# GPMC0_CFG register map
Vendor: Texas Instruments
Peripheral module from a debugger description file (folder am65x).
Registers are 32-bit, access per field, reset 0x0 unless marked. A register's access mark holds for its fields unless they carry their own. Offsets are as the file gives them; lines under a group give offsets from that group; [hi:lo] are bit positions; {n}, {i} and the like mark numbered series; 'fields as' and 'values as' point back to an identical list; <NAME> marks a mode.

## GPMC0_CFG
0x00 GPMC_REVISION ro reset 0x60 — This register contains the IP revision code.
  [31:0] REVISION — TI internal data. Identifies revision of peripheral.
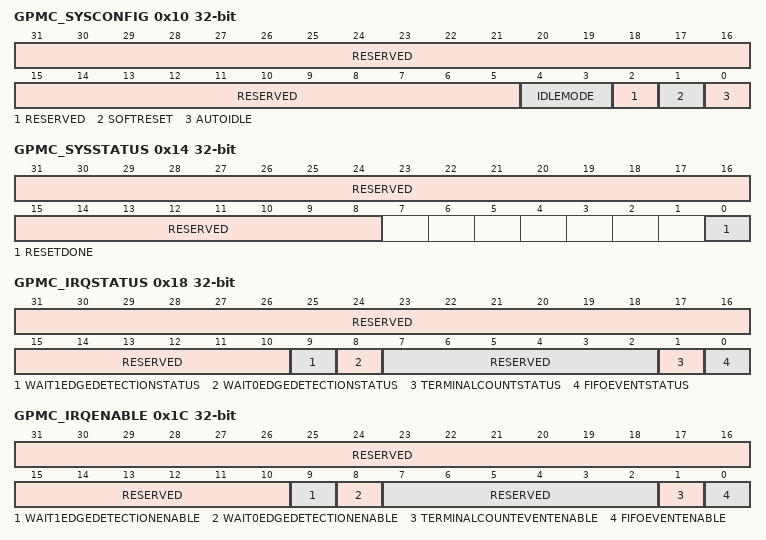
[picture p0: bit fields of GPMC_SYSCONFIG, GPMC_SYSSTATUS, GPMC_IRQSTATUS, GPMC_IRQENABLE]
0x10 GPMC_SYSCONFIG — Register related to module software reset and local power management.
  [31:5] RESERVED ro — Write 0s for future compatibility. Read returns 0.
  [4:3] IDLEMODE rw — 0h = Force-idle. A clock stop request is acknowledged unconditionally. 1h (R/W) = No-idle. A clock stop request is never acknowledged. 2h (R/W) = Smart-idle. Acknowledgment to a clock stop request is given based on the internal activity of the module. 3h (R/W) = Reserved. Do not use.
  [2] RESERVED ro — Write 0 for future compatibility Read returns 0.
  [1] SOFTRESET rw — Software reset. 0h (R/W) = Normal mode 1h (R/W) = The module is reset.
  [0] AUTOIDLE rw — Internal interface clock-gating strategy 0h (R/W) = Interface clock is free-running. 1h (R/W) = Automatic Interface clock gating strategy is applied, based on the interconnect activity.
0x14 GPMC_SYSSTATUS ro (reset mask 0xFFFFFFFE) — This register provides status information about the module, excluding the interrupt status information.
  [31:8] RESERVED — Read returns 0.
  [0] RESETDONE — Internal reset monitoring 0h (R) = Internal module reset is ongoing. 1h (R) = Reset is complete.
0x18 GPMC_IRQSTATUS — This interrupt status register regroups all the status of the module internal events that can generate an interrupt.
  [31:10] RESERVED ro — Write 0s for future compatibility. Read returns 0s.
  [9] WAIT1EDGEDETECTIONSTATUS rw — Status of the Wait1 Edge Detection interrupt Write: 0h = WAIT1EDGEDETECTIONSTATUS bit is unchanged. 1h = WAIT1EDGEDETECTIONSTATUS bit is reset. Read: 0h = A transition on WAIT1 input pin has not been detected. 1h = A transition on WAIT1 input pin has been detected.
  [8] WAIT0EDGEDETECTIONSTATUS rw — Status of the Wait0 Edge Detection interrupt Write: 0h = WAIT0EDGEDETECTIONSTATUS bit is unchanged. 1h = WAIT0EDGEDETECTIONSTATUS bit is reset. Read: 0h = A transition on WAIT0 input pin has not been detected. 1h = A transition on WAIT0 input pin has been detected.
  [7:2] RESERVED ro — Write 0s for future compatibility. Read returns 0s.
  [1] TERMINALCOUNTSTATUS rw — Status of the TerminalCountEvent interrupt Write: 0h = TERMINALCOUNTSTATUS bit is unchanged. 1h = TERMINALCOUNTSTATUS bit is reset. Read: 0h = Indicates that CountValue is greater than 0. 1h = Indicates that CountValue is equal to 0.
  [0] FIFOEVENTSTATUS rw — Status of the FIFOEvent interrupt Write: 0h = FIFOEVENTSTATUS bit is unchanged. 1h = FIFOEVENTSTATUS bit is reset. Read: 0h = Indicates that less than 1h = Indicates that at least
0x1C GPMC_IRQENABLE — The interrupt enable register allows to mask/unmask the module internal sources of interrupt, on a event-by-event basis.
  [31:10] RESERVED ro — Write 0s for future compatibility. Read returns 0s.
  [9] WAIT1EDGEDETECTIONENABLE rw — Enables the Wait1 Edge Detection interrupt 0h (R/W) = Wait1EdgeDetection interrupt is masked. 1h (R/W) = Wait1EdgeDetection event generates an interrupt if occurs.
  [8] WAIT0EDGEDETECTIONENABLE rw — Enables the Wait0 Edge Detection interrupt 0h (R/W) = Wait0EdgeDetection interrupt is masked. 1h (R/W) = Wait0EdgeDetection event generates an interrupt if occurs.
  [7:2] RESERVED ro — Write 0s for future compatibility. Read returns 0s.
  [1] TERMINALCOUNTEVENTENABLE rw — Enables TerminalCountEvent interrupt issuing in prefetch or write-posting mode 0h (R/W) = TerminalCountEvent interrupt is masked. 1h (R/W) = TerminalCountEvent interrupt is not masked.
  [0] FIFOEVENTENABLE rw — Enables the FIFOEvent interrupt 0h (R/W) = FIFOEvent interrupt is masked. 1h (R/W) = FIFOEvent interrupt is not masked.
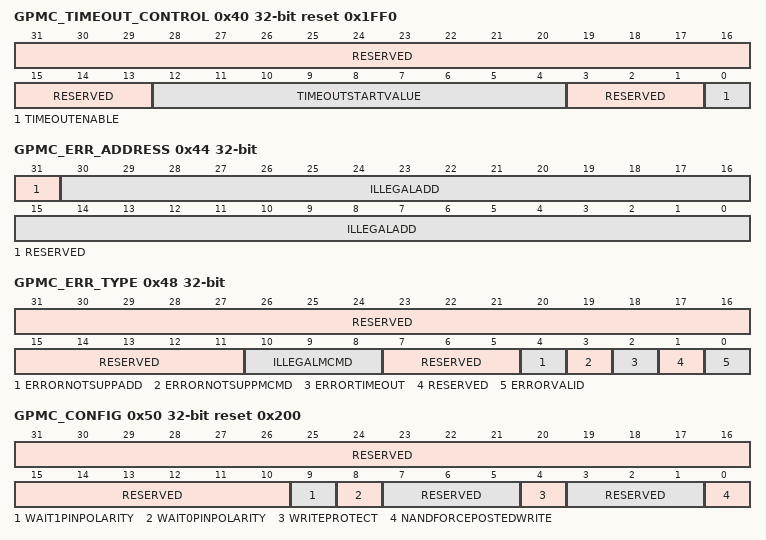
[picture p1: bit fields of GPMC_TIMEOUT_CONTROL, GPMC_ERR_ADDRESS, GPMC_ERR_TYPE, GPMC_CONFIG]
0x40 GPMC_TIMEOUT_CONTROL reset 0x1FF0 — The register allows the user to set the start value of the timeout counter.
  [31:13] RESERVED ro — Write 0s for future compatibility. Read returns 0s.
  [12:4] TIMEOUTSTARTVALUE rw — Start value of the time-out counter
  [3:1] RESERVED ro — Write 0s for future compatibility. Read returns 0s.
  [0] TIMEOUTENABLE rw — Enable bit of the TimeOut feature 0h (R/W) = TimeOut feature is disabled. 1h (R/W) = TimeOut feature is enabled.
0x44 GPMC_ERR_ADDRESS ro — The register stores the address of the illegal access when an error occurs.
  [31] RESERVED — Write 0s for future compatibility. Read returns 0.
  [30:0] ILLEGALADD — Address of illegal access
0x48 GPMC_ERR_TYPE access not given — The register stores the type of error when an error occurs.
  [31:11] RESERVED ro — Write 0s for future compatibility. Read returns 0s.
  [10:8] ILLEGALMCMD ro — System command of the transaction that caused the error
  [7:5] RESERVED ro — Write 0s for future compatibility. Read returns 0s.
  [4] ERRORNOTSUPPADD ro — Not supported address error 0h (R) = No error occurs. 1h (R) = The error is due to a nonsupported address.
  [3] ERRORNOTSUPPMCMD ro — Not supported command error 0h (R) = No error occurs. 1h (R) = The error is due to a nonsupported command
  [2] ERRORTIMEOUT ro — Time-out error 0h (R) = No error occurs. 1h (R) = The error is due to a timeout.
  [1] RESERVED ro — Write 0s for future compatibility. Read returns 0.
  [0] ERRORVALID — Error validity status - Must be explicitly cleared with a write 1 transaction 0h (R/W) = All error fields no longer valid 1h (R/W) = Error detected and logged in the other error fields (access RW1C)
0x50 GPMC_CONFIG reset 0x200 — The configuration register allows global configuration of the GPMC.
  [31:10] RESERVED ro — Write 0s for future compatibility. Read returns 0s.
  [9] WAIT1PINPOLARITY rw — Selects the polarity of input pin WAIT1 0h (R/W) = WAIT1 active low 1h (R/W) = WAIT1 active high
  [8] WAIT0PINPOLARITY rw — Selects the polarity of input pin WAIT0 0h (R/W) = WAIT0 active low 1h (R/W) = WAIT0 active high
  [7:5] RESERVED ro — Write 0s for future compatibility. Read returns 0s.
  [4] WRITEPROTECT rw — Controls the WP output pin level 0h (R/W) = nWP output pin is low 1h (R/W) = nWP output pin is high
  [3:1] RESERVED ro — Write 0s for future compatibility. Read returns 0s.
  [0] NANDFORCEPOSTEDWRITE rw — Enables the Force Posted Write feature to NAND Cmd/Add/Data location 0h (R/W) = Disables Force Posted Write 1h (R/W) = Enables Force Posted Write
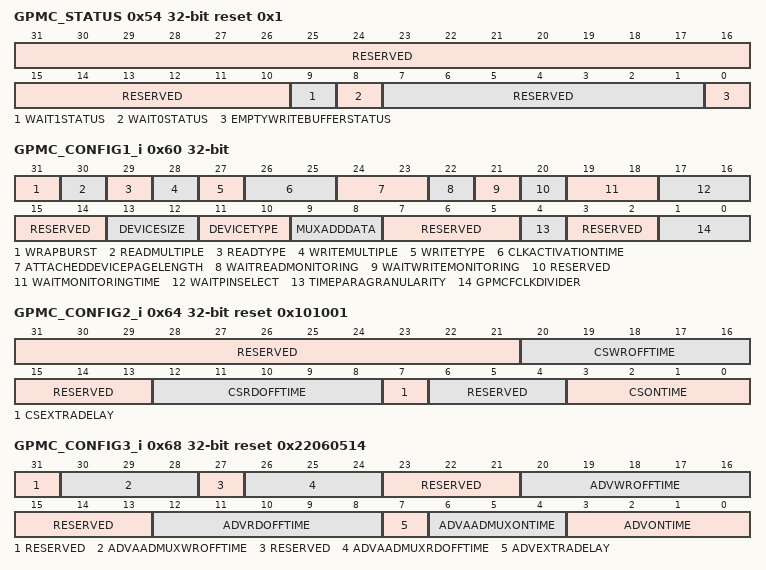
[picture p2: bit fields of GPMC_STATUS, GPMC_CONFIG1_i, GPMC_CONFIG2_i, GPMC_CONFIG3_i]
0x54 GPMC_STATUS ro reset 0x1 (reset mask 0xFFFFFCFF) — The status register provides global status bits of the GPMC.
  [31:10] RESERVED — Write 0s for future compatibility. Read returns 0s.
  [9] WAIT1STATUS — Is a copy of input pin WAIT1. (Reset value is WAIT1 input pin sampled at device reset.) 0h (R) = WAIT1 asserted (inactive state) 1h (R) = WAIT1 deasserted
  [8] WAIT0STATUS — Is a copy of input pin WAIT0. (Reset value is WAIT0 input pin sampled at device reset.) 0h (R) = WAIT0 asserted (inactive state) 1h (R) = WAIT0 deasserted
  [7:1] RESERVED — Write 0s for future compatibility. Reads returns 0
  [0] EMPTYWRITEBUFFERSTATUS — Stores the empty status of the write buffer 0h (R) = Write buffer is not empty. 1h (R) = Write buffer is empty.
0x60 GPMC_CONFIG1_i — The configuration register 1 sets signal control parameters per chip-select. Offset = 60h + (i * 30h), where: i = 0 to 3
  [31] WRAPBURST rw — Enables the wrapping burst capability. Must be set if the attached device is configured in wrapping burst 0h (R/W) = Synchronous wrapping burst not supported 1h (R/W) = Synchronous wrapping burst supported
  [30] READMULTIPLE rw — Selects the read single or multiple access 0h (R/W) = Single access 1h (R/W) = Multiple access (burst if synchronous, page if asynchronous)
  [29] READTYPE rw — Selects the read mode operation 0h (R/W) = Read asynchronous 1h (R/W) = Read synchronous
  [28] WRITEMULTIPLE rw — Selects the write single or multiple access 0h (R/W) = Single access 1h (R/W) = Multiple access (burst if synchronous, considered as single if asynchronous)
  [27] WRITETYPE rw — Selects the write mode operation 0h (R/W) = Write asynchronous 1h (R/W) = Write synchronous
  [26:25] CLKACTIVATIONTIME rw — Output GPMC_CLK activation time 0h (R/W) = First rising edge of GPMC_CLK at start access time 1h (R/W) = First rising edge of GPMC_CLK one GPMC_FICLK cycle after start access time 2h (R/W) = First rising edge of GPMC_CLK two GPMC_FICLK cycles after start access time 3h (R/W) = Reserved
  [24:23] ATTACHEDDEVICEPAGELENGTH rw — Specifies the attached device page (burst) length 0h (R/W) = 4 words 1h (R/W) = 8 words 2h (R/W) = 16 words 3h (R/W) = Reserved (1 word = interface size)
  [22] WAITREADMONITORING rw — Selects the Wait monitoring configuration for Read accesses 0h (R/W) = WAIT pin is not monitored for read accesses. 1h (R/W) = WAIT pin is monitored for read accesses.
  [21] WAITWRITEMONITORING rw — Selects the Wait monitoring configuration for Write accesses 0h (R/W) = WAIT pin is not monitored for write accesses. 1h (R/W) = WAIT pin is monitored for write accesses.
  [20] RESERVED ro — Write 0s for future compatibility. Read returns 0.
  [19:18] WAITMONITORINGTIME rw — Selects input pin Wait monitoring time 0h (R/W) = WAIT pin is monitored with valid data. 1h (R/W) = WAIT pin is monitored one GPMC_CLK cycle before valid data. 2h (R/W) = WAIT pin is monitored two GPMC_CLK cycle before valid data. 3h (R/W) = Reserved
  [17:16] WAITPINSELECT rw — Selects the input WAIT pin for this chip-select 0h (R/W) = Wait input pin is WAIT0. 1h (R/W) = Wait input pin is WAIT1. 2h, 3h = Reserved
  [15:14] RESERVED ro — Write 0s for future compatibility.
  [13:12] DEVICESIZE rw — Selects the device size attached 0h (R/W) = 8 bit 1h (R/W) = 16 bit 2h (R/W) = Reserved 3h (R/W) = Reserved
  [11:10] DEVICETYPE rw — Selects the attached device type 0h (R/W) = NOR flash-like, asynchronous and synchronous devices 1h (R/W) = Reserved 2h (R/W) = NAND flash-like devices, stream mode 3h (R/W) = Reserved
  [9:8] MUXADDDATA rw — Enables the address and data multiplexed protocol 0h (R/W) = Nonmultiplexed attached device 1h (R/W) = AAD-multiplexed protocol device 2h (R/W) = Address and data multiplexed attached device 3h (R/W) = Reserved
  [7:5] RESERVED ro — Write 0s for future compatibility. Read returns 0s.
  [4] TIMEPARAGRANULARITY rw — Signals timing latencies scalar factor (RD/WRCYCLETIME, RD/WRACCESSTIME, PAGEBURSTACCESSTIME, CSONTIME, CSRD/WROFFTIME, ADVONTIME, ADVRD/WROFFTIME, OEONTIME, OEOFFTIME, WEONTIME, WEOFFTIME, CYCLE2CYCLEDELAY, BUSTURNAROUND, TIMEOUTSTARTVALUE, WRDATAONADMUXBUS) 0h (R/W) = x1 latencies 1h (R/W) = x2 latencies
  [3:2] RESERVED ro — Write 0s for future compatibility. Read returns 0s.
  [1:0] GPMCFCLKDIVIDER rw — Divides the GPMC_FICLK clock 0h (R/W) = GPMC_CLK frequency = GPMC_FICLK frequency 1h (R/W) = GPMC_CLK frequency = GPMC_FICLK frequency / 2 2h (R/W) = GPMC_CLK frequency = GPMC_FICLK frequency / 3 3h (R/W) = GPMC_CLK frequency = GPMC_FICLK frequency /4
0x64 GPMC_CONFIG2_i reset 0x101001 — CS signal timing parameter configuration Offset = 64h + (i * 30h), where: i = 0 to 3
  [31:21] RESERVED ro — Write 0s for future compatibility.
  [20:16] CSWROFFTIME rw — CS i deassertion time from start cycle time for write accesses
  [15:13] RESERVED ro — Write 0s for future compatibility. Read returns 0s.
  [12:8] CSRDOFFTIME rw — CS i de-assertion time from start cycle time for read accesses
  [7] CSEXTRADELAY rw — CS i Add extra half-GPMC_FICLK cycle 0h (R/W) = CS i Timing control signal is not delayed 1h (R/W) = CS i Timing control signal is delayed of half GPMC_FICLK clock cycle
  [6:4] RESERVED ro — Write 0s for future compatibility. Read returns 0s.
  [3:0] CSONTIME rw — CS i assertion time from start cycle time
0x68 GPMC_CONFIG3_i reset 0x22060514 — nADV signal timing parameter configuration Offset = 68h + (i * 30h), where: i = 0 to 3
  [31] RESERVED ro — Write 0s for future compatibility. Read returns 0s.
  [30:28] ADVAADMUXWROFFTIME rw — nADV deassertion for first address phase when using the AAD-multiplexed protocol
  [27] RESERVED ro — Write 0s for future compatibility. Read returns 0s.
  [26:24] ADVAADMUXRDOFFTIME rw — nADV assertion for first address phase when using the AAD-multiplexed protocol
  [23:21] RESERVED ro — Write 0s for future compatibility. Read returns 0s.
  [20:16] ADVWROFFTIME rw — nADV deassertion time from start cycle time for write accesses
  [15:13] RESERVED ro — Write 0s for future compatibility. Read returns 0s.
  [12:8] ADVRDOFFTIME rw — nADV deassertion time from start cycle time for read accesses
  [7] ADVEXTRADELAY rw — nADV add extra half-GPMC_FICLK cycle 0h (R/W) = nADV timing control signal is not delayed 1h (R/W) = nADV timing control signal is delayed of half GPMC_FICLK clock cycle
  [6:4] ADVAADMUXONTIME rw — nADV assertion for first address phase when using the AAD-multiplexed protocol
  [3:0] ADVONTIME rw — nADV assertion time from start cycle time
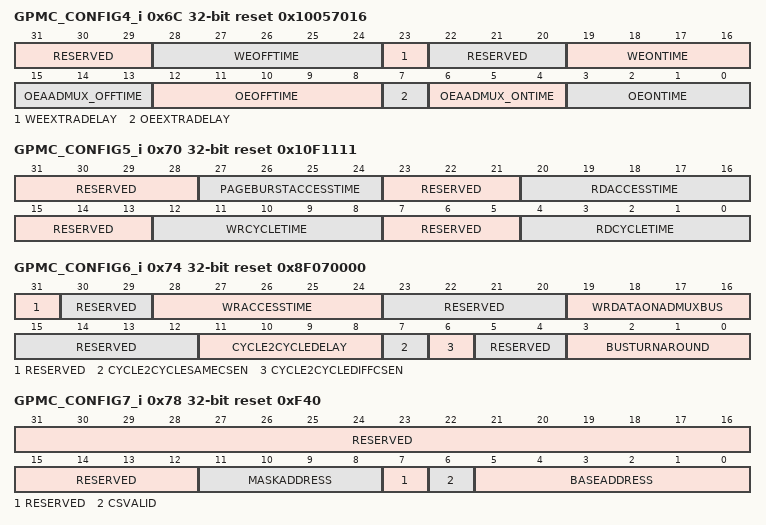
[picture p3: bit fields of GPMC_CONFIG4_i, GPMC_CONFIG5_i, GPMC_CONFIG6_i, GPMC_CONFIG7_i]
0x6C GPMC_CONFIG4_i reset 0x10057016 — nWE and nOE signals timing parameter configuration Offset = 6Ch + (i * 30h), where: i = 0 to 3
  [31:29] RESERVED ro — Write 0s for future compatibility. Read returns 0s.
  [28:24] WEOFFTIME rw — nWE deassertion time from start cycle time
  [23] WEEXTRADELAY rw — nWE add extra half-GPMC_FICLK cycle 0h (R/W) = nWE timing control signal is not delayed 1h (R/W) = nWE timing control signal is delayed of half-GPMC_FICLK clock cycle
  [22:20] RESERVED ro — Write 0s for future compatibility. Read returns 0s.
  [19:16] WEONTIME rw — nWE assertion time from start cycle time
  [15:13] OEAADMUX_OFFTIME rw — nOE deassertion time for the first address phase in an AAD-multiplexed access
  [12:8] OEOFFTIME rw — nOE deassertion time from start cycle time
  [7] OEEXTRADELAY rw — nOE add extra half-GPMC_FICLK cycle 0h (R/W) = nOE timing control signal is not delayed 1h (R/W) = nOE timing control signal is delayed of half-GPMC_FICLK clock cycle
  [6:4] OEAADMUX_ONTIME rw — nOE assertion time for the first address phase in an AAD-mux access
  [3:0] OEONTIME rw — nOE assertion time from start cycle time
0x70 GPMC_CONFIG5_i reset 0x10F1111 — RdAccessTime and CycleTime timing parameters configuration Offset = 70h + (i * 30h), where: i = 0 to 3
  [31:28] RESERVED ro — Write 0s for future compatibility. Read returns 0s.
  [27:24] PAGEBURSTACCESSTIME rw — Delay between successive words in a multiple access
  [23:21] RESERVED ro — Write 0s for future compatibility. Read returns 0s.
  [20:16] RDACCESSTIME rw — Delay between start cycle time and first data valid
  [15:13] RESERVED ro — Write 0s for future compatibility.
  [12:8] WRCYCLETIME rw — Total write cycle time
  [7:5] RESERVED ro — Write 0s for future compatibility. Read returns 0s.
  [4:0] RDCYCLETIME rw — Total read cycle time
0x74 GPMC_CONFIG6_i reset 0x8F070000 — WrAccessTime, WrDataOnADmuxBus, Cycle2Cycle and BusTurnAround parameters configuration Offset = 74h + (i * 30h), where: i = 0 to 3
  [31] RESERVED rw — TI Internal use - Do not modify.
  [30:29] RESERVED ro — Write 0s for future compatibility. Read returns 0s.
  [28:24] WRACCESSTIME rw — Delay from start access time to the GPMC_FICLK rising edge corresponding the GPMC_CLK rising edge used by the attached memory for the first data capture
  [23:20] RESERVED ro — Write 0s for future compatibility. Read returns 0s.
  [19:16] WRDATAONADMUXBUS rw — Specifies on which GPMC_FICLK rising edge the first data of the write is driven in the add/data mux bus
  [15:12] RESERVED ro — Write 0s for future compatibility. Read returns 0s.
  [11:8] CYCLE2CYCLEDELAY rw — Chip-select high pulse delay between successive accesses
  [7] CYCLE2CYCLESAMECSEN rw — Add CYCLE2CYCLEDELAY between successive accesses to the same chip-select (any access type) 0h (R/W) = No delay between the two accesses 1h (R/W) = Add CYCLE2CYCLEDELAY
  [6] CYCLE2CYCLEDIFFCSEN rw — Add CYCLE2CYCLEDELAY between successive accesses to a different chip-select (any access type) 0h (R/W) = No delay between the two accesses 1h (R/W) = Add CYCLE2CYCLEDELAY
  [5:4] RESERVED ro — Write 0s for future compatibility.
  [3:0] BUSTURNAROUND rw — Bus turnaround latency between successive accesses to the same chip-select (read to write) or to a different chip-select (read to read and read to write)
0x78 GPMC_CONFIG7_i reset 0xF40 — CS address mapping configuration Offset = 78h + (i * 30h), where: i = 0 to 3
  [31:12] RESERVED ro — Write 0s for future compatibility. Read returns 0s.
  [11:8] MASKADDRESS rw — CS mask address.
  [7] RESERVED ro — Write 0s for future compatibility. Read returns 0.
  [6] CSVALID rw — CS enable 0h (R/W) = CS disabled 1h (R/W) = CS enabled
  [5:0] BASEADDRESS rw — CSi base address where i = 0 to 3 (16-MB minimum granularity) bits [5-0] corresponds to A29, A28, A27, A26, A25, and A24. See
0x7C GPMC_NAND_COMMAND_i wo reset not defined — This register is not a true register, only an address location. Offset = 7Ch + (i * 30h), where: i = 0 to 3
  [31:0] GPMC_NAND_COMMAND — This register is not a true register, only an address location. Writing data at the
0x80 GPMC_NAND_ADDRESS_i wo reset not defined — This register is not a true register, only an address location. Offset = 80h + (i * 30h), where: i = 0 to 3
  [31:0] GPMC_NAND_ADDRESS — This register is not a true register, only an address location. Writing data at the
0x84 GPMC_NAND_DATA_i rw reset not defined — This register is not a true register, only an address location. Offset = 84h + (i * 30h), where: i = 0 to 3
  [31:0] GPMC_NAND_DATA — This register is not a true register, only an address location. Reading data from the
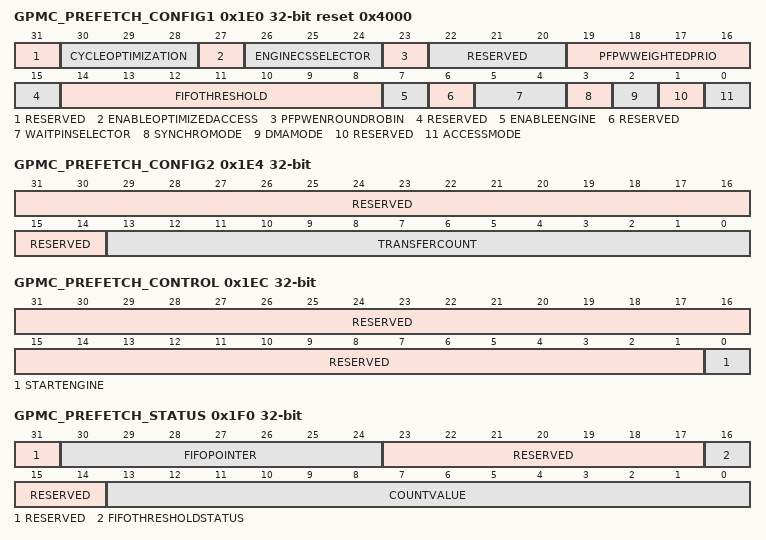
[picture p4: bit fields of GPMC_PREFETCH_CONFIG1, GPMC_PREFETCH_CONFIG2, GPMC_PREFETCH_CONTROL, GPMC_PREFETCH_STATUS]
0x1E0 GPMC_PREFETCH_CONFIG1 reset 0x4000 — Prefetch engine configuration 1 Some of the GPMC features described in this section may not be supported on this family of devices. For more information, see , GPMC Not Supported Features.
  [31] RESERVED ro — Write 0s for future compatibility. Read returns 0.
  [30:28] CYCLEOPTIMIZATION rw — Define the number of GPMC_FICLK cycles to be subtracted from RDCYCLETIME, WRCYCLETIME, RDACCESSTIME, CSRDOFFTIME, CSWROFFTIME, ADVRDOFFTIME, ADVWROFFTIME, OEOFFTIME, WEOFFTIME
  [27] ENABLEOPTIMIZEDACCESS rw — Enables access cycle optimization 0h (R/W) = Access cycle optimization is disabled. 1h (R/W) = Access cycle optimization is enabled.
  [26:24] ENGINECSSELECTOR rw — Selects the chip-select where Prefetch Postwrite engine is active
  [23] PFPWENROUNDROBIN rw — Enables the PFPW RoundRobin arbitration 0h (R/W) = Prefetch Postwrite engine round robin arbitration is disabled. 1h (R/W) = Prefetch Postwrite engine round robin arbitration is enabled.
  [22:20] RESERVED ro — Write 0s for future compatibility. Read returns 0s.
  [19:16] PFPWWEIGHTEDPRIO rw — When an arbitration occurs between a DMA and a PFPW engine access, the DMA is always serviced. If the PFPWEnRoundRobin is enabled,
  [15] RESERVED ro — Write 0s for future compatibility. Read returns 0.
  [14:8] FIFOTHRESHOLD rw — Selects the maximum number of bytes read from the FIFO or written to the FIFO by the host on a DMA or interrupt request
  [7] ENABLEENGINE rw — Enables the Prefetch Postwite engine 0h (R/W) = Prefetch Postwrite engine is disabled. 1h (R/W) = Prefetch Postwrite engine is enabled.
  [6] RESERVED ro — Write 0s for future compatibility. Read returns 0.
  [5:4] WAITPINSELECTOR rw — Select which wait pin edge detector should start the engine in synchronized mode 0h (R/W) = Selects Wait0 EdgeDetection 1h (R/W) = Selects Wait1 EdgeDetection 2h, 3h = Reserved
  [3] SYNCHROMODE rw — Selects when the engine starts the access to chip-select 0h (R/W) = Engine starts the access to chip-select as soon as STARTENGINE is set 1h (R/W) = Engine starts the access to chip-select as soon as STARTENGINE is set AND wait to nonwait edge detection on the selected wait pin
  [2] DMAMODE rw — Selects interrupt synchronization or DMA request synchronization 0h (R/W) = Interrupt synchronization is enabled. Only interrupt line is activated on FIFO threshold crossing. 1h (R/W) = DMA request synchronization is enabled. A DMA request protocol is used.
  [1] RESERVED ro — Write 0s for future compatibility. Read returns 0.
  [0] ACCESSMODE rw — Selects prefetch read or write-posting accesses 0h (R/W) = Prefetch read mode 1h (R/W) = Write-posting mode
0x1E4 GPMC_PREFETCH_CONFIG2 — Prefetch engine configuration 2
  [31:14] RESERVED ro — Write 0s for future compatibility. Read returns 0s.
  [13:0] TRANSFERCOUNT rw — Selects the number of bytes to be read or written by the engine to the selected chip-select
0x1EC GPMC_PREFETCH_CONTROL — Prefetch engine control
  [31:1] RESERVED ro — Write 0s for future compatibility. Read returns 0s.
  [0] STARTENGINE rw — Resets the FIFO pointer and starts the engine Write: 0h = Stops the engine. 1h = Resets the FIFO pointer to 0h in prefetch mode and 40h in postwrite mode and starts the engine. Read: 0h = Engine is stopped. 1h = Engine is running.
0x1F0 GPMC_PREFETCH_STATUS ro — Prefetch engine status
  [31] RESERVED — Write 0s for future compatibility. Read returns 0.
  [30:24] FIFOPOINTER — Number of available bytes to be read or number of free empty byte places to be written
  [23:17] RESERVED — Write 0s for future compatibility. Read returns 0s.
  [16] FIFOTHRESHOLDSTATUS — Set when FIFOPointer exceeds FIFOThreshold value 0h (R) = FIFOPointer smaller or equal to FIFOThreshold. Writing to this bit has no effect. 1h (R) = FIFOPointer greater than FIFOThreshold. Writing to this bit has no effect.
  [15:14] RESERVED — Write 0s for future compatibility. Read returns 0s.
  [13:0] COUNTVALUE — Number of remaining bytes to be read or to be written by the engine according to the TransferCount value
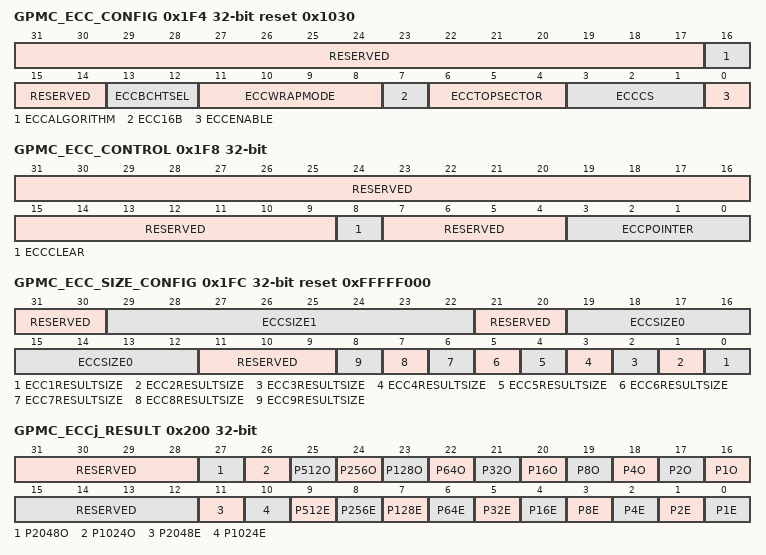
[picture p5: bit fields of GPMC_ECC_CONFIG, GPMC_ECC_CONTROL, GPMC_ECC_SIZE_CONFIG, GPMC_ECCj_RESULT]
0x1F4 GPMC_ECC_CONFIG reset 0x1030 — ECC configuration
  [31:17] RESERVED ro — Write 0s for future compatibility. Read returns 0s.
  [16] ECCALGORITHM rw — ECC algorithm used 0h (R/W) = Hamming code 1h (R/W) = BCH code
  [15:14] RESERVED ro — Write 0s for future compatibility. Read returns 0s.
  [13:12] ECCBCHTSEL rw — Error correction capability used for BCH 0h (R/W) = Up to 4 bits error correction (t = 4) 1h (R/W) = Up to 8 bits error correction (t = 8) 2h (R/W) = Up to 16 bits error correction (t = 16) 3h (R/W) = Reserved
  [11:8] ECCWRAPMODE rw — Spare area organization definition for the BCH algorithm. See the BCH syndrome/parity calculator module functional specification for more details
  [7] ECC16B rw — Selects an ECC calculated on 16 columns 0h (R/W) = ECC calculated on 8 columns 1h (R/W) = ECC calculated on 16 columns
  [6:4] ECCTOPSECTOR rw — Number of sectors to process with the BCH algorithm 1h = 2 sectors
  [3:1] ECCCS rw — Selects the CS where ECC is computed 0h (R/W) = CS0 1h (R/W) = CS1 2h (R/W) = CS2 3h (R/W) = CS3 Other: Reserved
  [0] ECCENABLE rw — Enables the ECC feature 0h (R/W) = ECC disabled 1h (R/W) = ECC enabled
0x1F8 GPMC_ECC_CONTROL — ECC control
  [31:9] RESERVED ro — Write 0s for future compatibility. Read returns 0s.
  [8] ECCCLEAR rw — Clear all ECC result registers
  [7:4] RESERVED ro — Write 0s for future compatibility. Read returns 0s.
  [3:0] ECCPOINTER rw — Selects ECC result register (Reads to this field give the dynamic position of the ECC pointer - Writes to this field select the ECC result register where the first ECC computation will be stored.); Writing other values disables the ECC engine (ECCENABLE bit of 0h (R/W) = Writing 0h disables the ECC engine (ECCENABLE bit of 1h (R/W) = ECC result register 1 selected 2h (R/W) = ECC result register 2 selected 3h (R/W) = ECC result register 3 selected 4h (R/W) = ECC result register 4 selected 5h (R/W) = ECC result register 5 selected 6h (R/W) = ECC result register 6 selected 7h (R/W) = ECC result register 7 selected 8h (R/W) = ECC result register 8 selected 9h (R/W) = ECC result register 9 selected
0x1FC GPMC_ECC_SIZE_CONFIG reset 0xFFFFF000 — ECC size
  [31:30] RESERVED ro — Write 0s for future compatibility. Read returns 3.
  [29:22] ECCSIZE1 rw — Defines Hamming code ECC size 1 in bytes
  [21:20] RESERVED ro — Write 0s for future compatibility. Read returns 3.
  [19:12] ECCSIZE0 rw — Defines Hamming code ECC size 0 in bytes
  [11:9] RESERVED ro — Write 0s for future compatibility. Read returns 0s.
  [n-1] ECC{n}RESULTSIZE rw (n=1..9) — Selects ECC size for ECC {n} result register 0h (R/W) = ECCSIZE0 selected 1h (R/W) = ECCSIZE1 selected
0x200 GPMC_ECCj_RESULT ro — ECC result register Offset = 200h + (j * 4h), where: j = 0 to 8
  [31:28] RESERVED — Write 0s for future compatibility. Read returns 0s.
  [27] P2048O — Odd row parity bit 2048, only used for ECC computed on 512 bytes
  [26] P1024O — Odd row parity bit 1024
  [25] P512O — Odd row parity bit 512
  [24] P256O — Odd row parity bit 256
  [23] P128O — Odd row parity bit 128
  [22] P64O — Odd row parity bit 64
  [21] P32O — Odd row parity bit 32
  [20] P16O — Odd row parity bit 16
  [19] P8O — Odd row parity bit 8
  [18] P4O — Odd Column Parity bit 4
  [17] P2O — Odd Column Parity bit 2
  [16] P1O — Odd Column Parity bit 1
  [15:12] RESERVED — Write 0s for future compatibility. Read returns 0s.
  [11] P2048E — Even row parity bit 2048, only used for ECC computed on 512 bytes
  [10] P1024E — Even row parity bit 1024
  [9] P512E — Even row parity bit 512
  [8] P256E — Even row parity bit 256
  [7] P128E — Even row parity bit 128
  [6] P64E — Even row parity bit 64
  [5] P32E — Even row parity bit 32
  [4] P16E — Even row parity bit 16
  [3] P8E — Even row parity bit 8
  [2] P4E — Even column parity bit 4
  [1] P2E — Even column parity bit 2
  [0] P1E — Even column parity bit 1
{0x240+4i} GPMC_BCH_RESULT{i}_i ro (i=0..2) — BCH ECC result (bits {32i} to {32i+31}) Offset = {4i+240}h + (i * 10h), where: i = 0 to 3
  [31:0] BCH_RESULT_{i} — BCH ECC result (bits {32i} to {32i+31})
0x24C GPMC_BCH_RESULT3_i ro — BCH ECC result (bits 96 to 127) Offset = 24Ch + (i * 10h), where: i = 0 to 3
  [31:0] BCH_RESULT_3 — BCH ECC result (bits 96 to 127)
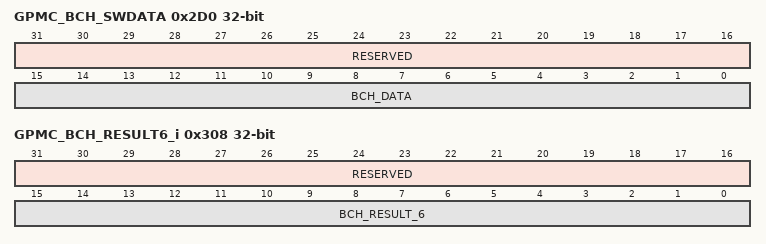
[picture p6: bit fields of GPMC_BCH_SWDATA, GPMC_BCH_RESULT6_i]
0x2D0 GPMC_BCH_SWDATA — This register is used to directly pass data to the BCH ECC calculator without accessing the actual NAND flash interface.
  [31:16] RESERVED ro — Write 0s for future compatibility. Read returns 0s.
  [15:0] BCH_DATA wo — Data to be included in the BCH calculation
0x300 GPMC_BCH_RESULT4_i ro — BCH ECC result (bits 128 to 159) Offset = 300h + (i * 10h), where: i = 0 to 3
  [31:0] BCH_RESULT_4 — BCH ECC result (bits 128 to 159)
0x304 GPMC_BCH_RESULT5_i ro — BCH ECC result (bits 160 to 191) Offset = 304h + (i * 10h), where: i = 0 to 3
  [31:0] BCH_RESULT_5 — BCH ECC result (bits 160 to 191)
0x308 GPMC_BCH_RESULT6_i ro — BCH ECC result (bits 192 to 207) Offset = 308h + (i * 10h), where: i = 0 to 3
  [31:16] RESERVED — Write 0s for future compatibility. Read returns 0s.
  [15:0] BCH_RESULT_6 — BCH ECC result (bits 192 to 207)
